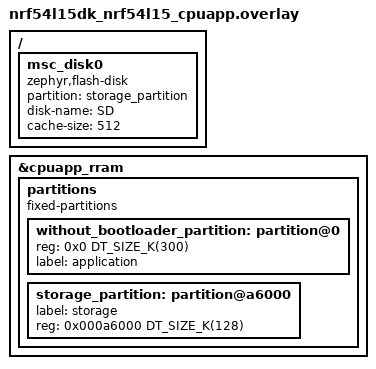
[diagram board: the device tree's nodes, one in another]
/*
 * Copyright (c) 2024 Nordic Semiconductor ASA
 *
 * SPDX-License-Identifier: Apache-2.0
 */

/* Because FAT FS needs at least 64kiB partition and default
 * storage_partition is 36kiB for this board, we need to reorganize
 * partitions to get at least 64KiB.
 */
/delete-node/ &without_bootloader_partition;
/delete-node/ &storage_partition;

&cpuapp_rram {
	partitions {
		compatible = "fixed-partitions";
		#address-cells = <1>;
		#size-cells = <1>;

		without_bootloader_partition: partition@0 {
			reg = <0x0 DT_SIZE_K(300)>;
			label = "application";
		};

		storage_partition: partition@a6000 {
			label = "storage";
			reg = <0x000a6000 DT_SIZE_K(128)>;
		};
	};
};

/ {
	msc_disk0 {
		status = "okay";
		compatible = "zephyr,flash-disk";
		partition = <&storage_partition>;
		disk-name = "SD";
		cache-size = <512>;
	};
};
